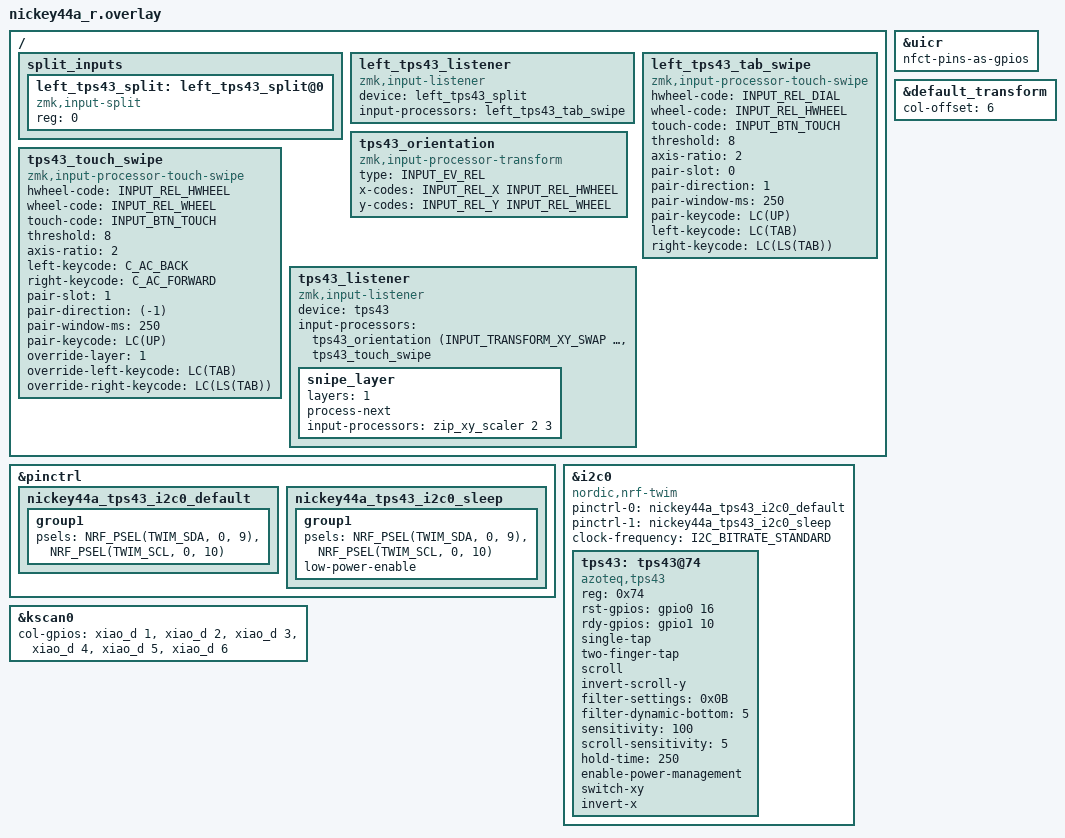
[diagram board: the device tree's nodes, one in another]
#include "nickey44a.dtsi"
#include <input/processors.dtsi>
#include <dt-bindings/pinctrl/nrf-pinctrl.h>
#include <dt-bindings/zmk/input_transform.h>
#include <dt-bindings/zmk/keys.h>
#include <zephyr/dt-bindings/input/input-event-codes.h>

/*
 * TPS43 FPC breakout wiring:
 *   SDA = XIAO NFC1/P0.09
 *   SCL = XIAO NFC2/P0.10
 *   RDY = XIAO P1.10
 *   NRST = XIAO P0.16
 */

&uicr {
    nfct-pins-as-gpios;
};

&pinctrl {
    nickey44a_tps43_i2c0_default: nickey44a_tps43_i2c0_default {
        group1 {
            psels = <NRF_PSEL(TWIM_SDA, 0, 9)>,
                    <NRF_PSEL(TWIM_SCL, 0, 10)>;
        };
    };

    nickey44a_tps43_i2c0_sleep: nickey44a_tps43_i2c0_sleep {
        group1 {
            psels = <NRF_PSEL(TWIM_SDA, 0, 9)>,
                    <NRF_PSEL(TWIM_SCL, 0, 10)>;
            low-power-enable;
        };
    };
};

/ {
    split_inputs {
        #address-cells = <1>;
        #size-cells = <0>;

        left_tps43_split: left_tps43_split@0 {
            compatible = "zmk,input-split";
            reg = <0>;
        };
    };

    left_tps43_listener: left_tps43_listener {
        compatible = "zmk,input-listener";
        device = <&left_tps43_split>;
        input-processors = <&left_tps43_tab_swipe>;
    };

    left_tps43_tab_swipe: left_tps43_tab_swipe {
        compatible = "zmk,input-processor-touch-swipe";
        #input-processor-cells = <0>;
        hwheel-code = <INPUT_REL_DIAL>;
        wheel-code = <INPUT_REL_HWHEEL>;
        touch-code = <INPUT_BTN_TOUCH>;
        threshold = <8>;
        axis-ratio = <2>;
        pair-slot = <0>;
        pair-direction = <1>; /* Physical left = positive DIAL. */
        pair-window-ms = <250>;
        pair-keycode = <LC(UP)>;
        /* Measured left pad: physical right swipe produces negative DIAL. */
        left-keycode = <LC(TAB)>;
        right-keycode = <LC(LS(TAB))>;
    };

    tps43_orientation: tps43_orientation {
        compatible = "zmk,input-processor-transform";
        #input-processor-cells = <1>;
        type = <INPUT_EV_REL>;
        x-codes = <INPUT_REL_X INPUT_REL_HWHEEL>;
        y-codes = <INPUT_REL_Y INPUT_REL_WHEEL>;
    };

    tps43_touch_swipe: tps43_touch_swipe {
        compatible = "zmk,input-processor-touch-swipe";
        #input-processor-cells = <0>;
        hwheel-code = <INPUT_REL_HWHEEL>;
        wheel-code = <INPUT_REL_WHEEL>;
        touch-code = <INPUT_BTN_TOUCH>;
        threshold = <8>;
        axis-ratio = <2>;
        left-keycode = <C_AC_BACK>;
        right-keycode = <C_AC_FORWARD>;
        pair-slot = <1>;
        pair-direction = <(-1)>; /* Physical right = negative HWHEEL. */
        pair-window-ms = <250>;
        pair-keycode = <LC(UP)>;
        override-layer = <1>;
        /* Physical right swipe is negative after orientation correction. */
        override-left-keycode = <LC(TAB)>;
        override-right-keycode = <LC(LS(TAB))>;
    };

    tps43_listener: tps43_listener {
        compatible = "zmk,input-listener";
        device = <&tps43>;
        /* Correct the measured controller output: left -> down, down -> left. */
        input-processors = <&tps43_orientation (INPUT_TRANSFORM_XY_SWAP |
                                             INPUT_TRANSFORM_X_INVERT |
                                             INPUT_TRANSFORM_Y_INVERT)>,
                           <&tps43_touch_swipe>; /* Firmware scroll inertia disabled. */

        snipe_layer {
            layers = <1>;
            process-next;
            input-processors = <&zip_xy_scaler 2 3>;
        };
    };
};

&i2c0 {
    status = "okay";
    compatible = "nordic,nrf-twim";
    pinctrl-0 = <&nickey44a_tps43_i2c0_default>;
    pinctrl-1 = <&nickey44a_tps43_i2c0_sleep>;
    pinctrl-names = "default", "sleep";
    clock-frequency = <I2C_BITRATE_STANDARD>;
    #address-cells = <1>;
    #size-cells = <0>;

    tps43: tps43@74 {
        compatible = "azoteq,tps43";
        reg = <0x74>;
        rst-gpios = <&gpio0 16 GPIO_ACTIVE_HIGH>;
        rdy-gpios = <&gpio1 10 GPIO_ACTIVE_HIGH>;

        single-tap;
        two-finger-tap;
        scroll;
        /* The listener swaps axes, so driver X controls host vertical scrolling. */
        invert-scroll-y;

        filter-settings = <0x0B>;
        filter-dynamic-bottom = <5>;
        sensitivity = <100>;
        scroll-sensitivity = <5>;
        hold-time = <250>;
        enable-power-management;
        /* Controller settings used when the listener's correction was measured. */
        switch-xy;
        invert-x;
    };
};

&default_transform {
    col-offset = <6>;
};

&kscan0 {
        col-gpios
            = <&xiao_d 1 GPIO_ACTIVE_HIGH>
            , <&xiao_d 2 GPIO_ACTIVE_HIGH>
            , <&xiao_d 3 GPIO_ACTIVE_HIGH>
            , <&xiao_d 4 GPIO_ACTIVE_HIGH>
            , <&xiao_d 5 GPIO_ACTIVE_HIGH>
            , <&xiao_d 6 GPIO_ACTIVE_HIGH>
            ;
};
